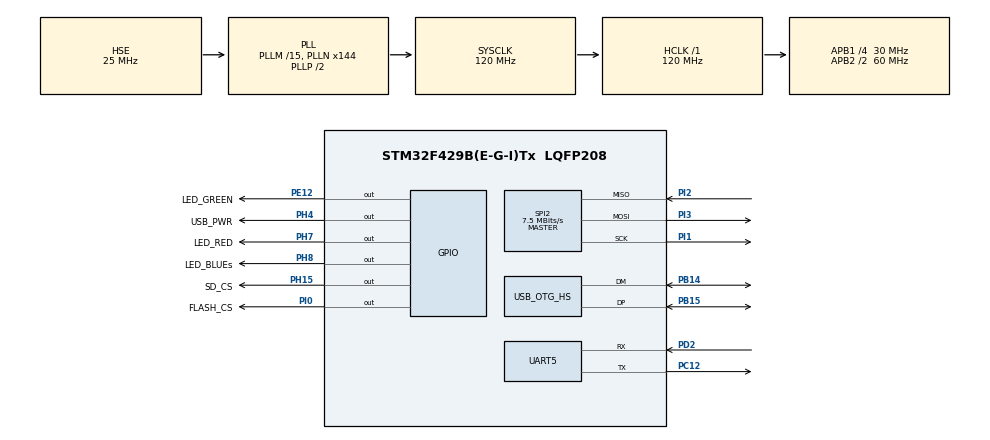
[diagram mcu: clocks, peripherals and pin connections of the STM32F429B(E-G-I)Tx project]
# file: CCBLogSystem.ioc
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FATFS._CODE_PAGE=936
FATFS._MAX_SS=4096
FATFS._USE_LFN=2
FREERTOS.Tasks01=ledTask,0,1024,ledStartTask,Default,NULL,Dynamic,NULL,NULL
Mcu.Family=STM32F4
Mcu.Name=STM32F429B(E-G-I)Tx
Mcu.Package=LQFP208
NVIC.OTG_HS_EP1_IN_IRQn=true\:5\:0\:false\:false\:true\:true\:true\:true
NVIC.OTG_HS_EP1_OUT_IRQn=true\:5\:0\:false\:false\:true\:true\:true\:true
NVIC.OTG_HS_IRQn=true\:5\:0\:false\:false\:true\:true\:false\:true
NVIC.PriorityGroup=NVIC_PRIORITYGROUP_4
NVIC.TIM1_UP_TIM10_IRQn=true\:0\:0\:false\:false\:true\:false\:false\:true
NVIC.TimeBase=TIM1_UP_TIM10_IRQn
NVIC.TimeBaseIP=TIM1
NVIC.UART5_IRQn=true\:5\:0\:false\:false\:true\:true\:true\:true
PA13.Mode=Serial_Wire
PA13.Signal=SYS_JTMS-SWDIO
PA14.Mode=Serial_Wire
PA14.Signal=SYS_JTCK-SWCLK
PB14.Mode=Host_FS
PB14.Signal=USB_OTG_HS_DM
PB15.Mode=Host_FS
PB15.Signal=USB_OTG_HS_DP
PC12.Mode=Asynchronous
PC12.Signal=UART5_TX
PD2.Mode=Asynchronous
PD2.Signal=UART5_RX
PE12.GPIO_Label=LED_GREEN
PE12.PinState=GPIO_PIN_SET
PE12.Signal=GPIO_Output
PH0/OSC_IN.Mode=HSE-External-Oscillator
PH0/OSC_IN.Signal=RCC_OSC_IN
PH1/OSC_OUT.Mode=HSE-External-Oscillator
PH1/OSC_OUT.Signal=RCC_OSC_OUT
PH15.GPIO_Label=SD_CS
PH15.PinState=GPIO_PIN_SET
PH15.Signal=GPIO_Output
PH4.GPIO_Label=USB_PWR
PH4.PinState=GPIO_PIN_SET
PH4.Signal=GPIO_Output
PH7.GPIO_Label=LED_RED
PH7.PinState=GPIO_PIN_SET
PH7.Signal=GPIO_Output
PH8.GPIO_Label=LED_BLUEs
PH8.PinState=GPIO_PIN_SET
PH8.Signal=GPIO_Output
PI0.GPIO_Label=FLASH_CS
PI0.PinState=GPIO_PIN_SET
PI0.Signal=GPIO_Output
PI1.Mode=Full_Duplex_Master
PI1.Signal=SPI2_SCK
PI2.Mode=Full_Duplex_Master
PI2.Signal=SPI2_MISO
PI3.Mode=Full_Duplex_Master
PI3.Signal=SPI2_MOSI
ProjectManager.HeapSize=0x1000
ProjectManager.StackSize=0x1000
ProjectManager.TargetToolchain=MDK-ARM V5.27
RCC.48MHZClocksFreq_Value=48000000
RCC.AHBFreq_Value=120000000
RCC.APB1CLKDivider=RCC_HCLK_DIV4
RCC.APB1Freq_Value=30000000
RCC.APB1TimFreq_Value=60000000
RCC.APB2CLKDivider=RCC_HCLK_DIV2
RCC.APB2Freq_Value=60000000
RCC.APB2TimFreq_Value=120000000
RCC.CortexFreq_Value=120000000
RCC.HCLKFreq_Value=120000000
RCC.HSE_VALUE=25000000
RCC.HSI_VALUE=16000000
RCC.LSE_VALUE=32768
RCC.PLLM=15
RCC.PLLN=144
RCC.PLLQ=5
RCC.SYSCLKFreq_VALUE=120000000
RCC.SYSCLKSource=RCC_SYSCLKSOURCE_PLLCLK
RCC.VCOOutputFreq_Value=240000000
SPI2.BaudRatePrescaler=SPI_BAUDRATEPRESCALER_4
SPI2.CLKPhase=SPI_PHASE_1EDGE
SPI2.CLKPolarity=SPI_POLARITY_LOW
SPI2.CalculateBaudRate=7.5 MBits/s
SPI2.Direction=SPI_DIRECTION_2LINES
SPI2.Mode=SPI_MODE_MASTER
SPI2.VirtualType=VM_MASTER
UART5.VirtualMode=Asynchronous
USB_HOST.BSP.number=1
USB_HOST.USBH_HandleTypeDef-MSC_HS=hUsbHostHS
USB_HOST.VirtualModeHS=Msc
USB_HOST0.BSP.STBoard=false
USB_HOST0.BSP.api=Unknown
USB_HOST0.BSP.i2caddr=0
USB_HOST0.BSP.instance=PH4
USB_HOST0.BSP.ip=GPIO
USB_HOST0.BSP.mode=Output
USB_HOST0.BSP.name=Drive_VBUS_HS
USB_HOST0.BSP.solution=PH4
USB_OTG_HS.VirtualMode-Host_FS=Host_FS
VP_FATFS_VS_Generic.Mode=User_defined
VP_FATFS_VS_USB.Mode=USB
VP_FREERTOS_VS_CMSIS_V1.Mode=CMSIS_V1
VP_RTC_VS_RTC_Activate.Mode=RTC_Enabled
VP_RTC_VS_RTC_Calendar.Mode=RTC_Calendar
VP_SYS_VS_tim1.Mode=TIM1
VP_USB_HOST_VS_USB_HOST_MSC_HS.Mode=MSC_HS
board=custom

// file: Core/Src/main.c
/* USER CODE BEGIN Header */
/**
  ******************************************************************************
  * @file           : main.c
  * @brief          : Main program body
  ******************************************************************************
  * @attention
  *
  * <h2><center>&copy; Copyright (c) 2021 STMicroelectronics.
  * All rights reserved.</center></h2>
  *
  * This software component is licensed by ST under Ultimate Liberty license
  * SLA0044, the "License"; You may not use this file except in compliance with
  * the License. You may obtain a copy of the License at:
  *                             www.st.com/SLA0044
  *
  ******************************************************************************
  */
/* USER CODE END Header */
#include "main.h"
#include "cmsis_os.h"
#include "fatfs.h"
#include "rtc.h"
#include "spi.h"
#include "usart.h"
#include "usb_host.h"
#include "gpio.h"

void SystemClock_Config(void);
void MX_FREERTOS_Init(void);

int main(void)
{

  /* MCU Configuration--------------------------------------------------------*/

  /* Reset of all peripherals, Initializes the Flash interface and the Systick. */
  HAL_Init();

  /* Configure the system clock */
  SystemClock_Config();

  /* Initialize all configured peripherals */
  MX_GPIO_Init();
  MX_FATFS_Init();
  MX_SPI2_Init();
  MX_UART5_Init();
  MX_RTC_Init();

  /* Call init function for freertos objects (in freertos.c) */
  MX_FREERTOS_Init();
  /* Start scheduler */
  osKernelStart();

  /* We should never get here as control is now taken by the scheduler */
  /* Infinite loop */
  while (1)
  {

  }
}

void SystemClock_Config(void)
{
  RCC_OscInitTypeDef RCC_OscInitStruct = {0};
  RCC_ClkInitTypeDef RCC_ClkInitStruct = {0};

  /** Configure the main internal regulator output voltage
  */
  __HAL_RCC_PWR_CLK_ENABLE();
  __HAL_PWR_VOLTAGESCALING_CONFIG(PWR_REGULATOR_VOLTAGE_SCALE3);
  /** Initializes the RCC Oscillators according to the specified parameters
  * in the RCC_OscInitTypeDef structure.
  */
  RCC_OscInitStruct.OscillatorType = RCC_OSCILLATORTYPE_LSI|RCC_OSCILLATORTYPE_HSE;
  RCC_OscInitStruct.HSEState = RCC_HSE_ON;
  RCC_OscInitStruct.LSIState = RCC_LSI_ON;
  RCC_OscInitStruct.PLL.PLLState = RCC_PLL_ON;
  RCC_OscInitStruct.PLL.PLLSource = RCC_PLLSOURCE_HSE;
  RCC_OscInitStruct.PLL.PLLM = 15;
  RCC_OscInitStruct.PLL.PLLN = 144;
  RCC_OscInitStruct.PLL.PLLP = RCC_PLLP_DIV2;
  RCC_OscInitStruct.PLL.PLLQ = 5;
  if (HAL_RCC_OscConfig(&RCC_OscInitStruct) != HAL_OK)
  {
    Error_Handler();
  }
  /** Initializes the CPU, AHB and APB buses clocks
  */
  RCC_ClkInitStruct.ClockType = RCC_CLOCKTYPE_HCLK|RCC_CLOCKTYPE_SYSCLK
                              |RCC_CLOCKTYPE_PCLK1|RCC_CLOCKTYPE_PCLK2;
  RCC_ClkInitStruct.SYSCLKSource = RCC_SYSCLKSOURCE_PLLCLK;
  RCC_ClkInitStruct.AHBCLKDivider = RCC_SYSCLK_DIV1;
  RCC_ClkInitStruct.APB1CLKDivider = RCC_HCLK_DIV4;
  RCC_ClkInitStruct.APB2CLKDivider = RCC_HCLK_DIV2;

  if (HAL_RCC_ClockConfig(&RCC_ClkInitStruct, FLASH_LATENCY_3) != HAL_OK)
  {
    Error_Handler();
  }
}

void HAL_TIM_PeriodElapsedCallback(TIM_HandleTypeDef *htim)
{
  if (htim->Instance == TIM1) {
    HAL_IncTick();
  }
}

void Error_Handler(void)
{
  __disable_irq();
  while (1)
  {
  }
}

/************************ (C) COPYRIGHT STMicroelectronics *****END OF FILE****/

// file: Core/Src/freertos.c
/* USER CODE BEGIN Header */
/**
  ******************************************************************************
  * File Name          : freertos.c
  * Description        : Code for freertos applications
  ******************************************************************************
  * @attention
  *
  * <h2><center>&copy; Copyright (c) 2021 STMicroelectronics.
  * All rights reserved.</center></h2>
  *
  * This software component is licensed by ST under Ultimate Liberty license
  * SLA0044, the "License"; You may not use this file except in compliance with
  * the License. You may obtain a copy of the License at:
  *                             www.st.com/SLA0044
  *
  ******************************************************************************
  */
/* USER CODE END Header */

#include "FreeRTOS.h"
#include "task.h"
#include "main.h"
#include "cmsis_os.h"

/* USER CODE BEGIN Includes */
#include "usart.h"
#include "fatfs.h"
#include "spi.h"
#include "w25qxx.h"
#include "usb_host.h"

/* USER CODE END Includes */

/* USER CODE BEGIN Variables */
#define CCB_LOG_PRINT(fmt, ...)  CCB_logSystemPrint(__LINE__, __FILE__, __FUNCTION__, fmt, ##__VA_ARGS__)

/* USER CODE END Variables */
osThreadId ledTaskHandle;

/* USER CODE BEGIN FunctionPrototypes */
void ReadID(void);

/* USER CODE END FunctionPrototypes */

void ledStartTask(void const * argument);

extern void MX_USB_HOST_Init(void);
void MX_FREERTOS_Init(void); /* (MISRA C 2004 rule 8.1) */

/* GetIdleTaskMemory prototype (linked to static allocation support) */
void vApplicationGetIdleTaskMemory( StaticTask_t **ppxIdleTaskTCBBuffer, StackType_t **ppxIdleTaskStackBuffer, uint32_t *pulIdleTaskStackSize );

/* USER CODE BEGIN GET_IDLE_TASK_MEMORY */
static StaticTask_t xIdleTaskTCBBuffer;
static StackType_t xIdleStack[configMINIMAL_STACK_SIZE];

void vApplicationGetIdleTaskMemory( StaticTask_t **ppxIdleTaskTCBBuffer, StackType_t **ppxIdleTaskStackBuffer, uint32_t *pulIdleTaskStackSize )
{
  *ppxIdleTaskTCBBuffer = &xIdleTaskTCBBuffer;
  *ppxIdleTaskStackBuffer = &xIdleStack[0];
  *pulIdleTaskStackSize = configMINIMAL_STACK_SIZE;
  /* place for user code */
}
/* USER CODE END GET_IDLE_TASK_MEMORY */

void MX_FREERTOS_Init(void) {

  /* Create the thread(s) */
  /* definition and creation of ledTask */
  osThreadDef(ledTask, ledStartTask, osPriorityNormal, 0, 1024);
  ledTaskHandle = osThreadCreate(osThread(ledTask), NULL);

}

void ledStartTask(void const * argument)
{
  /* init code for USB_HOST */
  MX_USB_HOST_Init();
  /* USER CODE BEGIN ledStartTask */
  printf(" mian�� \r\n");
  HAL_GPIO_WritePin(USB_PWR_GPIO_Port, USB_PWR_Pin, GPIO_PIN_SET);

  //SD_init();

  /* Infinite loop */
  for(;;)
  {
    HAL_GPIO_TogglePin(LED_RED_GPIO_Port, LED_RED_Pin);
	//W25qxx_Init();
	//mount_disk();
	//format_disk();
	//create_file();
	//read_file();
	//USB_hardWareTest();
	//CCB_logSystemPrint("CCB Log System Test!!!!", __LINE__, __FILE__, __FUNCTION__);
	//CCB_LOG_PRINT("CCB Log System Test!!!!\r\n");

	 //CCB_LOG_PRINT("CCB Log System Test Num:%d\r\n", 123);
	 //CCB_logSystemPrint("CCB Log System Test\r\n", __LINE__, __FILE__, __FUNCTION__);

	  //CCB_logSystemPrint("CCB Log System Test num :%d\r\n", __LINE__, __FILE__, __FUNCTION__, 123);
	CCB_LOG_PRINT("CCB Log System Test!!!!\r\n");

	CCB_LOG_PRINT("output string:%s\r\n", "Chenzx!");

	CCB_LOG_PRINT("output int:%d\r\n", 6);

	osDelay(500);

	//SD_test();
	//printf("Hello World!!\r\n");
  }
  /* USER CODE END ledStartTask */
}

/************************ (C) COPYRIGHT STMicroelectronics *****END OF FILE****/
